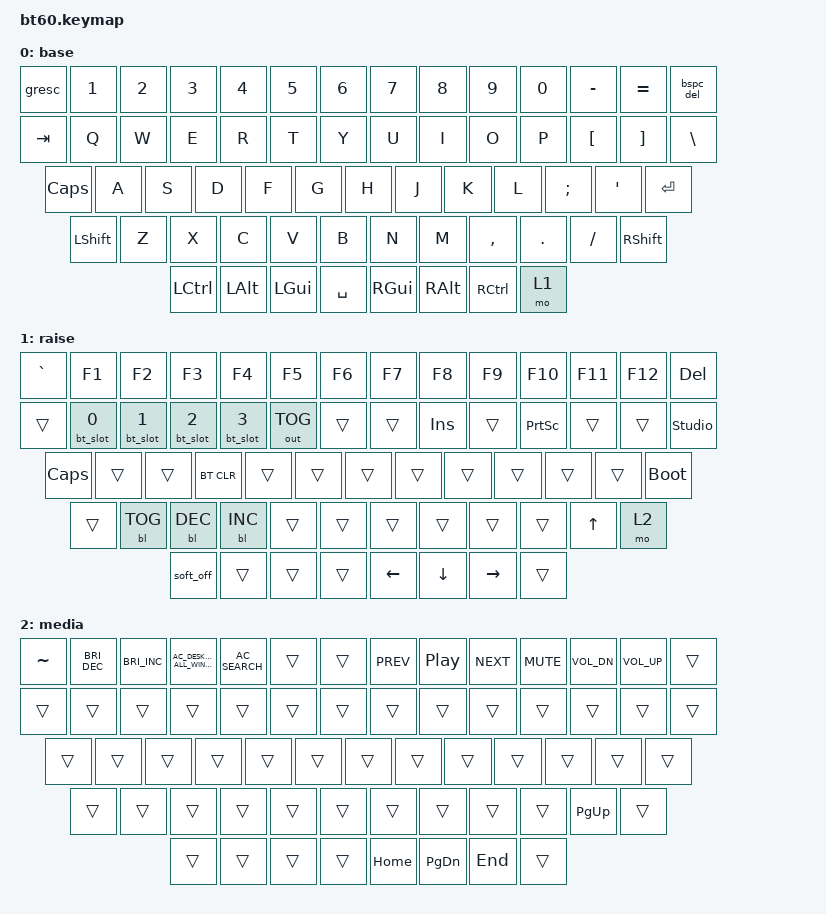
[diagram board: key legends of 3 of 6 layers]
#include <behaviors.dtsi>
#include <dt-bindings/zmk/keys.h>
#include <dt-bindings/zmk/bt.h>
#include <dt-bindings/zmk/rgb.h>
#include <dt-bindings/zmk/backlight.h>
#include <dt-bindings/zmk/outputs.h>
#include "ryong-behaviors.dtsi"

#define ANSI

// Soft Off (official ZMK behavior): on Fn + Left Ctrl by default (raise layer). Hold it, then release, to
// turn off; the hold time is set in ryong-behaviors.json (key.ryong.com → Combos & Macros → Settings).
// It can be moved to any key with ZMK Studio; turning back on is Fn + that same key held 3 s
// (src/bt60_power_confirm.c). Only Fn wakes the keyboard, so Fn is always part of turning on.

/ {
  chosen {
    zmk,physical-layout = &layout_60_ansi;
  };

  behaviors {
    // Backspace; with Shift held it sends Delete (Shift itself is not sent with it).
    bspc_del: backspace_delete {
      compatible = "zmk,behavior-mod-morph";
      #binding-cells = <0>;
      bindings = <&kp BSPC>, <&kp DEL>;
      mods = <(MOD_LSFT|MOD_RSFT)>;
      display-name = "Backspace/Delete";
    };
  };

  keymap {
    compatible = "zmk,keymap";

    base {
      display-name = "base";
      bindings = <
        &gresc &kp N1 &kp N2 &kp N3 &kp N4 &kp N5 &kp N6 &kp N7 &kp N8 &kp N9 &kp N0 &kp MINUS &kp EQUAL &bspc_del
        &kp TAB  &kp Q  &kp W  &kp E  &kp R  &kp T  &kp Y  &kp U  &kp I  &kp O  &kp P  &kp LBKT &kp RBKT &kp BSLH
        &kp CAPS &kp A  &kp S  &kp D  &kp F  &kp G  &kp H  &kp J  &kp K  &kp L  &kp SEMI &kp SQT &kp RET
        &kp LSHFT &kp Z  &kp X  &kp C  &kp V  &kp B  &kp N  &kp M  &kp COMMA &kp DOT &kp FSLH &kp RSHFT
        &kp LCTRL &kp LALT &kp LGUI &kp SPACE &kp RGUI &kp RALT &kp RCTRL &mo 1
      >;
    };

    raise {
      display-name = "raise";
      bindings = <
        &kp GRAVE &kp F1 &kp F2 &kp F3 &kp F4 &kp F5 &kp F6 &kp F7 &kp F8 &kp F9 &kp F10 &kp F11 &kp F12 &kp DEL
        &trans &bt_slot 0 &bt_slot 1 &bt_slot 2 &bt_slot 3 &out OUT_TOG &trans &trans &kp INS &trans &kp PSCRN &trans &trans &studio_unlock
        &kp CAPS &trans &trans &bt BT_CLR &trans &trans &trans &trans &trans &trans &trans &trans &bootloader
        &trans &bl BL_TOG &bl BL_DEC &bl BL_INC &trans &trans &trans &trans &trans &trans &kp UP &mo 2
        &soft_off &trans &trans &trans &kp LEFT &kp DOWN &kp RIGHT &trans
      >;
    };

    media {
      display-name = "media";
      bindings = <
        &kp TILDE &kp C_BRI_DEC &kp C_BRI_INC &kp C_AC_DESKTOP_SHOW_ALL_WINDOWS &kp C_AC_SEARCH &trans &trans &kp C_PREV &kp C_PLAY_PAUSE &kp C_NEXT &kp C_MUTE &kp C_VOL_DN &kp C_VOL_UP &trans
        &trans &trans &trans &trans &trans &trans &trans &trans &trans &trans &trans &trans &trans &trans
        &trans &trans &trans &trans &trans &trans &trans &trans &trans &trans &trans &trans &trans
        &trans &trans &trans &trans &trans &trans &trans &trans &trans &trans &kp PG_UP &trans
        &trans &trans &trans &trans &kp HOME &kp PG_DN &kp END &trans
      >;
    };

    layer4 {
      display-name = "layer4";
      bindings = <
        &trans &trans &trans &trans &trans &trans &trans &trans &trans &trans &trans &trans &trans &trans
        &trans &trans &trans &trans &trans &trans &trans &trans &trans &trans &trans &trans &trans
        &trans &trans &trans &trans &trans &trans &trans &trans &trans &trans &trans &trans &trans
        &trans &trans &trans &trans &trans &trans &trans &trans &trans &trans &trans &trans
        &trans &trans &trans &trans &trans &trans &trans &trans
      >;
    };

    layer5 {
      display-name = "layer5";
      bindings = <
        &trans &trans &trans &trans &trans &trans &trans &trans &trans &trans &trans &trans &trans &trans
        &trans &trans &trans &trans &trans &trans &trans &trans &trans &trans &trans &trans &trans
        &trans &trans &trans &trans &trans &trans &trans &trans &trans &trans &trans &trans &trans
        &trans &trans &trans &trans &trans &trans &trans &trans &trans &trans &trans &trans
        &trans &trans &trans &trans &trans &trans &trans &trans
      >;
    };

    layer6 {
      display-name = "layer6";
      bindings = <
        &trans &trans &trans &trans &trans &trans &trans &trans &trans &trans &trans &trans &trans &trans
        &trans &trans &trans &trans &trans &trans &trans &trans &trans &trans &trans &trans &trans
        &trans &trans &trans &trans &trans &trans &trans &trans &trans &trans &trans &trans &trans
        &trans &trans &trans &trans &trans &trans &trans &trans &trans &trans &trans &trans
        &trans &trans &trans &trans &trans &trans &trans &trans
      >;
    };
  };
};
